# FM33FK5XX register map
File version: 1.0
CPU: Cortex-M33 r1p0, little endian, MPU, FPU, 3 interrupt priority bits
Registers are 32-bit, read-write, reset 0x0 unless marked. A register's access mark holds for its fields unless they carry their own. Offsets are from the block's base; [hi:lo] are bit positions; {n}, {i} and the like mark numbered series; 'fields as' and 'values as' point back to an identical list.

## CAN — CAN module information
Base 0x40019400
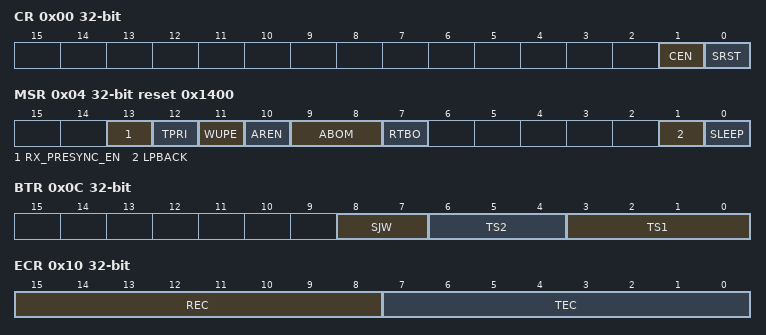
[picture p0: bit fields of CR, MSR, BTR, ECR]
0x00 CR — CANControlRegister
  [1] CEN — CEN field description
  [0] SRST — SRST field description
0x04 MSR reset 0x1400 — CANmodeselectregister
  [13] RX_PRESYNC_EN — RX_PRESYNC_EN field description
  [12] TPRI — TPRI field description
  [11] WUPE — WUPE field description
  [10] AREN — AREN field description
  [9:8] ABOM — ABOM field description
  [7] RTBO — RTBO field description
  [1] LPBACK — LPBACK field description
  [0] SLEEP — SLEEP field description
0x08 BRPR — CANBaudratePrescalerRegister
  [7:0] BRP — BRP field description
0x0C BTR — CANBitTimingRegister
  [8:7] SJW — SJW field description
  [6:4] TS2 — TS2 field description
  [3:0] TS1 — TS1 field description
0x10 ECR ro — CANErrorCounterRegister
  [15:8] REC — REC field description
  [7:0] TEC — TEC field description
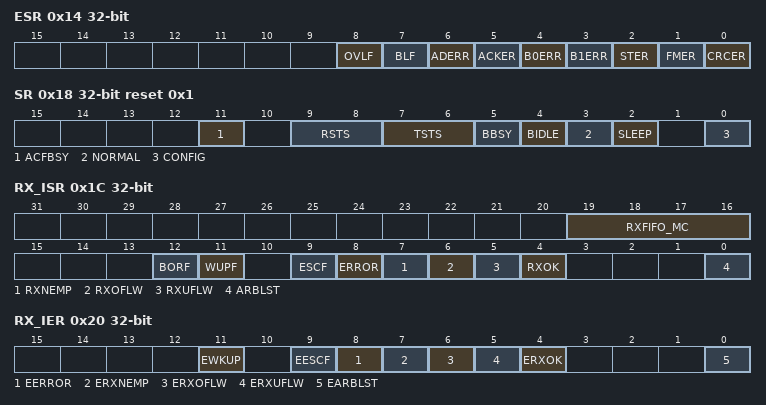
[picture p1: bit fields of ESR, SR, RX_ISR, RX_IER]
0x14 ESR — CANErrorStatusRegister
  [8] OVLF — OVLF field description
  [7] BLF — BLF field description
  [6] ADERR — ADERR field description
  [5] ACKER — ACKER field description
  [4] B0ERR — B0ERR field description
  [3] B1ERR — B1ERR field description
  [2] STER — STER field description
  [1] FMER — FMER field description
  [0] CRCER — CRCER field description
0x18 SR ro reset 0x1 — CANStatusRegister
  [11] ACFBSY — ACFBSY field description
  [9:8] RSTS — RSTS field description
  [7:6] TSTS — TSTS field description
  [5] BBSY — BBSY field description
  [4] BIDLE — BIDLE field description
  [3] NORMAL — NORMAL field description
  [2] SLEEP — SLEEP field description
  [0] CONFIG — CONFIG field description
0x1C RX_ISR ro — CANInterruptStatusRegister
  [19:16] RXFIFO_MC — RXFIFO_MC field description
  [12] BORF — BORF field description
  [11] WUPF — WUPF field description
  [9] ESCF — ESCF field description
  [8] ERROR — ERROR field description
  [7] RXNEMP — RXNEMP field description
  [6] RXOFLW — RXOFLW field description
  [5] RXUFLW — RXUFLW field description
  [4] RXOK — RXOK field description
  [0] ARBLST — ARBLST field description
0x20 RX_IER — CANInterruptEnableRegister
  [11] EWKUP — EWKUP field description
  [9] EESCF — EESCF field description
  [8] EERROR — EERROR field description
  [7] ERXNEMP — ERXNEMP field description
  [6] ERXOFLW — ERXOFLW field description
  [5] ERXUFLW — ERXUFLW field description
  [4] ERXOK — ERXOK field description
  [0] EARBLST — EARBLST field description
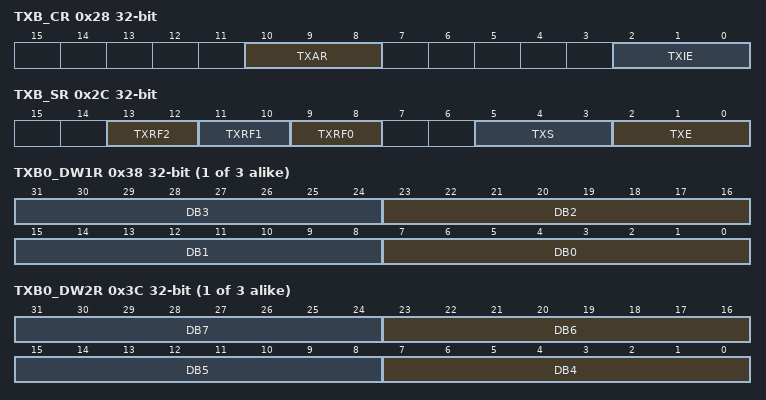
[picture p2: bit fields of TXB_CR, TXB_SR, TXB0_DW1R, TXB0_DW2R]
0x28 TXB_CR — CANTransmitBufferControlRegister
  [10:8] TXAR — TXAR field description
  [2:0] TXIE — TXIE field description
0x2C TXB_SR access per field — CANTransmitBufferStatusRegister
  [13:12] TXRF2 ro — TXRF2 field description
  [11:10] TXRF1 ro — TXRF1 field description
  [9:8] TXRF0 ro — TXRF0 field description
  [5:3] TXS ro — TXS field description
  [2:0] TXE rw — TXE field description
{0x30+0x10*i} TXB{i}_IDR wo (i=0..2) — CANTransmitBuffer{i}IDRegister
  [31:0] IDR — IDR field description
{0x34+0x10*i} TXB{i}_DLCR wo (i=0..2) — CANTransmitBuffer{i}DLCRegister
  [3:0] DLC — DLC field description
{0x38+0x10*i} TXB{i}_DW1R wo (i=0..2) — CANTransmitBuffer{i}DataWord1Register
  [8n+7:8n] DB{n} (n=0..3) — DB{n} field description
{0x3C+0x10*i} TXB{i}_DW2R wo (i=0..2) — CANTransmitBuffer{i}DataWord2Register
  [8n-25:8n-32] DB{n} (n=4..7) — DB{n} field description
0x60 AFCR — AcceptanceFilterControlRegister
  [15:0] UAF — UAF field description
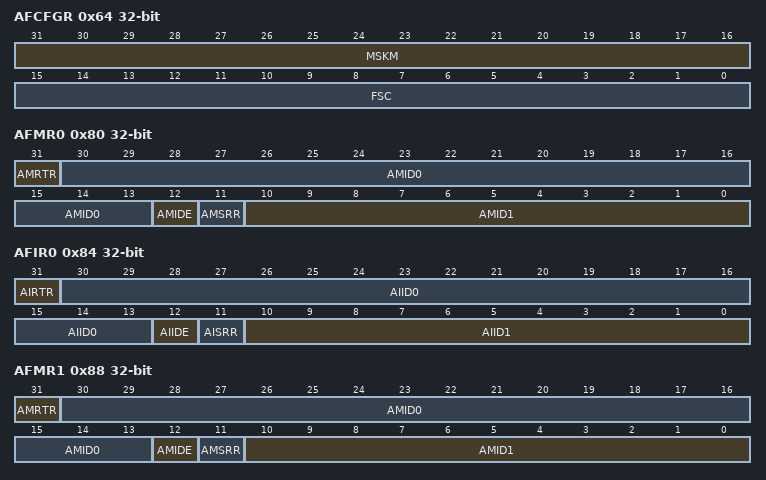
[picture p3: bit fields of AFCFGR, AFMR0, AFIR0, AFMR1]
0x64 AFCFGR — AcceptanceFilterConfigRegister
  [31:16] MSKM — MSKM field description
  [15:0] FSC — FSC field description
0x80 AFMR0 — AcceptanceFilterMaskRegister0
  [31] AMRTR — AMRTR field description
  [30:13] AMID0 — AMID0 field description
  [12] AMIDE — AMIDE field description
  [11] AMSRR — AMSRR field description
  [10:0] AMID1 — AMID1 field description
0x84 AFIR0 — AcceptanceFilterIDRegister0
  [31] AIRTR — AIRTR field description
  [30:13] AIID0 — AIID0 field description
  [12] AIIDE — AIIDE field description
  [11] AISRR — AISRR field description
  [10:0] AIID1 — AIID1 field description
0x88 AFMR1 — AcceptanceFilterMaskRegister1
  fields as AFMR0
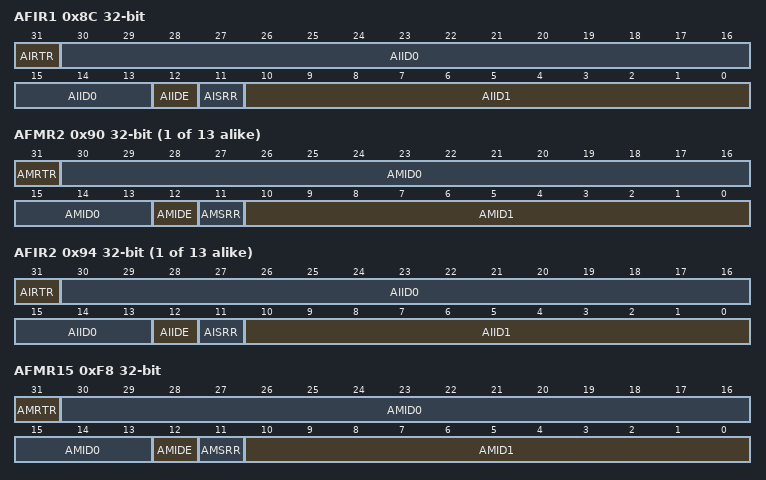
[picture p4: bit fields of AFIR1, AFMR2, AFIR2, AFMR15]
0x8C AFIR1 — AcceptanceFilterIDRegister1
  fields as AFIR0
{0x80+8i} AFMR{i} (i=2..14)
  fields as AFMR0
{0x84+8i} AFIR{i} (i=2..14)
  fields as AFIR0
0xF8 AFMR15 — AcceptanceFilterMaskRegister15
  fields as AFMR0
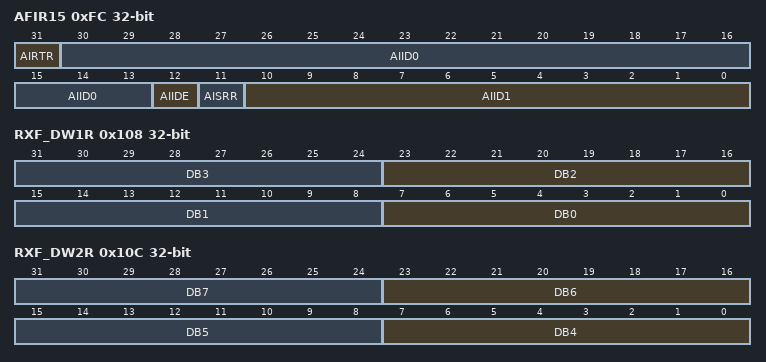
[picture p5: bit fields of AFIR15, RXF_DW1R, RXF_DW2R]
0xFC AFIR15 — AcceptanceFilterIDRegister15
  fields as AFIR0
0x100 RXF_IDR wo — CANRXFIFOIDRegister
  [31:0] IDR — IDR field description
0x104 RXF_DLCR wo — CANRXFIFODLCRegister
  [3:0] DLC — DLC field description
0x108 RXF_DW1R wo — CANRXFIFODataWord1Register
  [8n+7:8n] DB{n} (n=0..3) — DB{n} field description
0x10C RXF_DW2R wo — CANRXFIFODataWord2Register
  [8n-25:8n-32] DB{n} (n=4..7) — DB{n} field description
